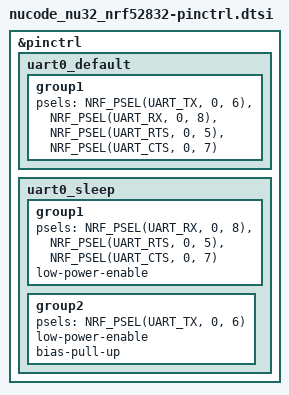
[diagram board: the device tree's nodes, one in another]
/*
 * Copyright (c) 2026 NUCODE Co., Ltd.
 * SPDX-License-Identifier: Apache-2.0
 */

&pinctrl {
	uart0_default: uart0_default {
		group1 {
			psels = <NRF_PSEL(UART_TX, 0, 6)>,
				<NRF_PSEL(UART_RX, 0, 8)>,
				<NRF_PSEL(UART_RTS, 0, 5)>,
				<NRF_PSEL(UART_CTS, 0, 7)>;
		};
	};

	uart0_sleep: uart0_sleep {
		group1 {
			psels = <NRF_PSEL(UART_RX, 0, 8)>,
				<NRF_PSEL(UART_RTS, 0, 5)>,
				<NRF_PSEL(UART_CTS, 0, 7)>;
			low-power-enable;
		};

		group2 {
			psels = <NRF_PSEL(UART_TX, 0, 6)>;
			low-power-enable;
			bias-pull-up;
		};
	};
};
